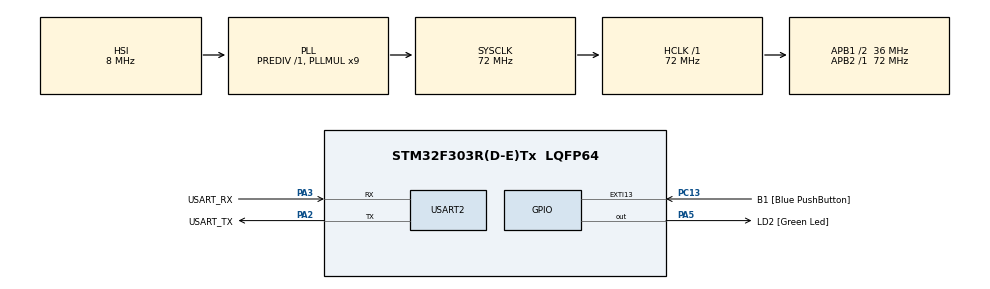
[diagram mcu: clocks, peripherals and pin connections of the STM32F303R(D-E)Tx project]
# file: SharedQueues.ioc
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Mcu.Family=STM32F3
PC15-OSC32_OUT.Mode=LSE-External-Oscillator
PA2.GPIO_PuPd=GPIO_NOPULL
FREERTOS.Queues01=myQueue01,16,uint16_t,0,Dynamic,NULL,NULL
VP_SYS_VS_tim6.Mode=TIM6
RCC.CortexFreq_Value=72000000
FREERTOS.Tasks01=queue01,24,128,ManageQueue01,Default,NULL,Dynamic,NULL,NULL;queue02,24,128,ManageQueue02,Default,NULL,Dynamic,NULL,NULL
NVIC.TIM6_DAC_IRQn=true\:0\:0\:false\:false\:true\:false\:false\:true
PC13.Signal=GPXTI13
PA14.GPIO_Label=TCK
RCC.SYSCLKSourceVirtual=RCC_SYSCLKSOURCE_PLLCLK
PA3.GPIO_PuPd=GPIO_NOPULL
PA2.GPIO_Speed=GPIO_SPEED_FREQ_LOW
PC13.GPIO_Label=B1 [Blue PushButton]
RCC.APB1CLKDivider=RCC_HCLK_DIV2
PC14-OSC32_IN.Signal=RCC_OSC32_IN
PA3.GPIO_Speed=GPIO_SPEED_FREQ_LOW
ProjectManager.StackSize=0x400
VP_FREERTOS_VS_CMSIS_V2.Mode=CMSIS_V2
PA13.Signal=SYS_JTMS-SWDIO
PA3.Mode=Asynchronous
ProjectManager.TargetToolchain=STM32CubeIDE
PA3.GPIO_Mode=GPIO_MODE_AF_PP
RCC.HCLKFreq_Value=72000000
RCC.APB2TimFreq_Value=72000000
RCC.USBFreq_Value=72000000
PC15-OSC32_OUT.Signal=RCC_OSC32_OUT
RCC.AHBFreq_Value=72000000
PF0-OSC_IN.Mode=HSE-External-Clock-Source
PA5.Signal=GPIO_Output
RCC.HSE_VALUE=8000000
board=NUCLEO-F303RE
USART2.VirtualMode-Asynchronous=VM_ASYNC
RCC.RCC_PLLsource_Clock_Source_FROM_HSE=RCC_HSE_PREDIV_DIV2
RCC.PLLMUL=RCC_PLL_MUL9
RCC.APB2Freq_Value=72000000
PC14-OSC32_IN.Mode=LSE-External-Oscillator
PA14.Mode=Serial_Wire
PA5.GPIO_PuPd=GPIO_NOPULL
PA13.Mode=Serial_Wire
Mcu.Name=STM32F303R(D-E)Tx
PA2.Signal=USART2_TX
PA13.GPIO_Label=TMS
PB3.Signal=SYS_JTDO-TRACESWO
RCC.SYSCLKFreq_VALUE=72000000
Mcu.Package=LQFP64
NVIC.TimeBase=TIM6_DAC_IRQn
PA5.GPIO_Label=LD2 [Green Led]
PC13.GPIO_ModeDefaultEXTI=GPIO_MODE_IT_FALLING
PA2.GPIO_Label=USART_TX
NVIC.TimeBaseIP=TIM6
PA14.Signal=SYS_JTCK-SWCLK
ProjectManager.HeapSize=0x200
RCC.HSI_VALUE=8000000
RCC.PLLP=RCC_PLLP_DIV4
PA5.GPIO_Speed=GPIO_SPEED_FREQ_LOW
RCC.PLLQ=7
NVIC.PriorityGroup=NVIC_PRIORITYGROUP_4
RCC.PLLM=8
RCC.PLLN=336
RCC.APB1TimFreq_Value=72000000
PA2.Mode=Asynchronous
PF0-OSC_IN.Signal=RCC_OSC_IN
RCC.APB1Freq_Value=36000000
PA5.GPIO_Mode=GPIO_MODE_OUTPUT_PP
PF1-OSC_OUT.Signal=RCC_OSC_OUT
PA3.GPIO_Label=USART_RX
PA3.Signal=USART2_RX
PA2.GPIO_Mode=GPIO_MODE_AF_PP
PB3.GPIO_Label=SWO

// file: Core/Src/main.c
/* USER CODE BEGIN Header */
/**
 ******************************************************************************
 * @file           : main.c
 * @brief          : Main program body
 ******************************************************************************
 * @attention
 *
 * <h2><center>&copy; Copyright (c) 2021 STMicroelectronics.
 * All rights reserved.</center></h2>
 *
 * This software component is licensed by ST under Ultimate Liberty license
 * SLA0044, the "License"; You may not use this file except in compliance with
 * the License. You may obtain a copy of the License at:
 *                             www.st.com/SLA0044
 *
 ******************************************************************************
 */
/* USER CODE END Header */
#include "main.h"
#include "cmsis_os.h"

/* USER CODE BEGIN Includes */
#include "FreeRTOS.h"
#include "queue.h"
#include <stdio.h>
#include <string.h>
/* USER CODE END Includes */

UART_HandleTypeDef huart2;

/* Definitions for queue01 */
osThreadId_t queue01Handle;
const osThreadAttr_t queue01_attributes = {
		.name = "queue01",
		.priority = (osPriority_t) osPriorityNormal,
		.stack_size = 2048
};
/* Definitions for queue02 */
osThreadId_t queue02Handle;
const osThreadAttr_t queue02_attributes = {
		.name = "queue02",
		.priority = (osPriority_t) osPriorityNormal,
		.stack_size = 512
};
/* Definitions for myQueue01 */
osMessageQueueId_t myQueue01Handle;
const osMessageQueueAttr_t myQueue01_attributes = {
		.name = "myQueue01"
};

void SystemClock_Config(void);
static void MX_GPIO_Init(void);
static void MX_USART2_UART_Init(void);
void ManageQueue01(void *argument);
void ManageQueue02(void *argument);

int main(void)
{

	/* MCU Configuration--------------------------------------------------------*/

	/* Reset of all peripherals, Initializes the Flash interface and the Systick. */
	HAL_Init();

	/* Configure the system clock */
	SystemClock_Config();

	/* Initialize all configured peripherals */
	MX_GPIO_Init();
	MX_USART2_UART_Init();

	/* Init scheduler */
	osKernelInitialize();

	/* Create the queue(s) */
	/* creation of myQueue01 */
	myQueue01Handle = osMessageQueueNew (16, sizeof(uint16_t), &myQueue01_attributes);

	/* Create the thread(s) */
	/* creation of queue01 */
	queue01Handle = osThreadNew(ManageQueue01, NULL, &queue01_attributes);

	/* creation of queue02 */
	queue02Handle = osThreadNew(ManageQueue02, NULL, &queue02_attributes);

	/* Start scheduler */
	osKernelStart();

	/* We should never get here as control is now taken by the scheduler */
	/* Infinite loop */
	while (1) {

	}
}

void SystemClock_Config(void)
{
	RCC_OscInitTypeDef RCC_OscInitStruct = {0};
	RCC_ClkInitTypeDef RCC_ClkInitStruct = {0};
	RCC_PeriphCLKInitTypeDef PeriphClkInit = {0};

	/** Initializes the RCC Oscillators according to the specified parameters
	 * in the RCC_OscInitTypeDef structure.
	 */
	RCC_OscInitStruct.OscillatorType = RCC_OSCILLATORTYPE_HSI;
	RCC_OscInitStruct.HSIState = RCC_HSI_ON;
	RCC_OscInitStruct.HSICalibrationValue = RCC_HSICALIBRATION_DEFAULT;
	RCC_OscInitStruct.PLL.PLLState = RCC_PLL_ON;
	RCC_OscInitStruct.PLL.PLLSource = RCC_PLLSOURCE_HSI;
	RCC_OscInitStruct.PLL.PLLMUL = RCC_PLL_MUL9;
	RCC_OscInitStruct.PLL.PREDIV = RCC_PREDIV_DIV1;
	if (HAL_RCC_OscConfig(&RCC_OscInitStruct) != HAL_OK)
	{
		Error_Handler();
	}
	/** Initializes the CPU, AHB and APB buses clocks
	 */
	RCC_ClkInitStruct.ClockType = RCC_CLOCKTYPE_HCLK|RCC_CLOCKTYPE_SYSCLK
			|RCC_CLOCKTYPE_PCLK1|RCC_CLOCKTYPE_PCLK2;
	RCC_ClkInitStruct.SYSCLKSource = RCC_SYSCLKSOURCE_PLLCLK;
	RCC_ClkInitStruct.AHBCLKDivider = RCC_SYSCLK_DIV1;
	RCC_ClkInitStruct.APB1CLKDivider = RCC_HCLK_DIV2;
	RCC_ClkInitStruct.APB2CLKDivider = RCC_HCLK_DIV1;

	if (HAL_RCC_ClockConfig(&RCC_ClkInitStruct, FLASH_LATENCY_2) != HAL_OK)
	{
		Error_Handler();
	}
	PeriphClkInit.PeriphClockSelection = RCC_PERIPHCLK_USART2;
	PeriphClkInit.Usart2ClockSelection = RCC_USART2CLKSOURCE_PCLK1;
	if (HAL_RCCEx_PeriphCLKConfig(&PeriphClkInit) != HAL_OK)
	{
		Error_Handler();
	}
}

static void MX_USART2_UART_Init(void)
{

	huart2.Instance = USART2;
	huart2.Init.BaudRate = 38400;
	huart2.Init.WordLength = UART_WORDLENGTH_8B;
	huart2.Init.StopBits = UART_STOPBITS_1;
	huart2.Init.Parity = UART_PARITY_NONE;
	huart2.Init.Mode = UART_MODE_TX_RX;
	huart2.Init.HwFlowCtl = UART_HWCONTROL_NONE;
	huart2.Init.OverSampling = UART_OVERSAMPLING_16;
	huart2.Init.OneBitSampling = UART_ONE_BIT_SAMPLE_DISABLE;
	huart2.AdvancedInit.AdvFeatureInit = UART_ADVFEATURE_NO_INIT;
	if (HAL_UART_Init(&huart2) != HAL_OK)
	{
		Error_Handler();
	}

}

static void MX_GPIO_Init(void)
{
	GPIO_InitTypeDef GPIO_InitStruct = {0};

	/* GPIO Ports Clock Enable */
	__HAL_RCC_GPIOC_CLK_ENABLE();
	__HAL_RCC_GPIOF_CLK_ENABLE();
	__HAL_RCC_GPIOA_CLK_ENABLE();
	__HAL_RCC_GPIOB_CLK_ENABLE();

	/*Configure GPIO pin Output Level */
	HAL_GPIO_WritePin(LD2_GPIO_Port, LD2_Pin, GPIO_PIN_RESET);

	/*Configure GPIO pin : B1_Pin */
	GPIO_InitStruct.Pin = B1_Pin;
	GPIO_InitStruct.Mode = GPIO_MODE_IT_FALLING;
	GPIO_InitStruct.Pull = GPIO_NOPULL;
	HAL_GPIO_Init(B1_GPIO_Port, &GPIO_InitStruct);

	/*Configure GPIO pin : LD2_Pin */
	GPIO_InitStruct.Pin = LD2_Pin;
	GPIO_InitStruct.Mode = GPIO_MODE_OUTPUT_PP;
	GPIO_InitStruct.Pull = GPIO_NOPULL;
	GPIO_InitStruct.Speed = GPIO_SPEED_FREQ_LOW;
	HAL_GPIO_Init(LD2_GPIO_Port, &GPIO_InitStruct);

}

void ManageQueue01(void *argument)
{
	/* USER CODE BEGIN 5 */
	/* Infinite loop */
	char msg[1000];
	uint16_t number ;
	//sprintf(msg, "Start get\n");

	HAL_UART_Transmit(&huart2, (uint8_t*) msg, strlen(msg), HAL_MAX_DELAY);
	for (;;) {
		osMessageQueueGet(myQueue01Handle, &number, NULL, 0);
		sprintf(msg, "Receive value: number =  %hu\n", number);

		HAL_UART_Transmit(&huart2, (uint8_t*) msg, strlen(msg), HAL_MAX_DELAY);

		osThreadYield();
	}

}

void ManageQueue02(void *argument)
{
	/* USER CODE BEGIN ManageQueue02 */
	/* Infinite loop */
	char msg[1000];
	uint16_t number;

	//sprintf(msg, "Start put\n");
	HAL_UART_Transmit(&huart2, (uint8_t*) msg, strlen(msg), HAL_MAX_DELAY);
	for (;;) {

		number =310;
		sprintf(msg, "Put value: number =  %hu\n", number);

		osMessageQueuePut(myQueue01Handle, &number, 0, 100);

		HAL_UART_Transmit(&huart2, (uint8_t*) msg, strlen(msg), HAL_MAX_DELAY);

		osThreadYield();
	}

	/* USER CODE END ManageQueue02 */
}
void HAL_TIM_PeriodElapsedCallback(TIM_HandleTypeDef *htim)
{
	if (htim->Instance == TIM6) {
		HAL_IncTick();
	}
}

void Error_Handler(void)
{
	__disable_irq();
	while (1) {
	}
}

/************************ (C) COPYRIGHT STMicroelectronics *****END OF FILE****/
